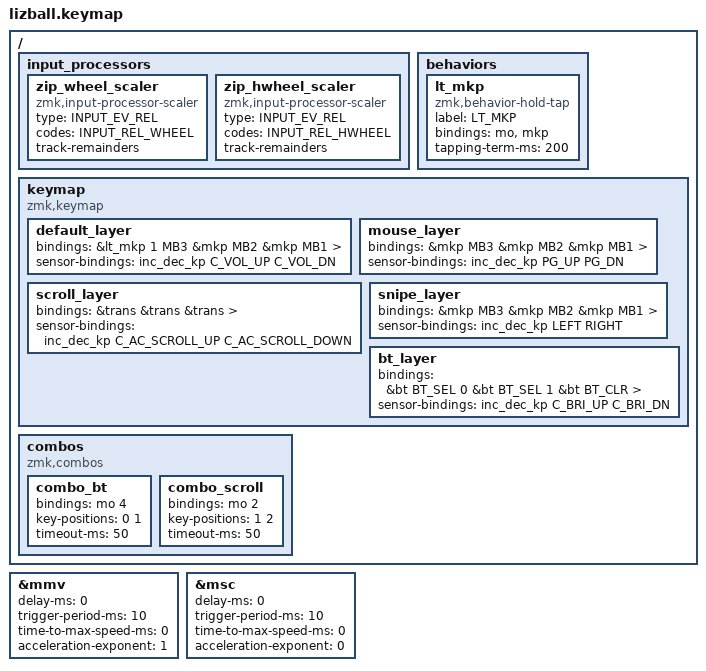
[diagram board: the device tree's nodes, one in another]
#include <dt-bindings/zmk/mouse.h>

// Default mouse movement and scroll values
#define ZMK_POINTING_DEFAULT_MOVE_VAL 800
#define ZMK_POINTING_DEFAULT_SCRL_VAL 120

#include <input/processors.dtsi>
#include <zephyr/dt-bindings/input/input-event-codes.h>
#include <behaviors.dtsi>
#include <dt-bindings/zmk/bt.h>
#include <dt-bindings/zmk/keys.h>
#include <dt-bindings/zmk/pointing.h>

// Mouse movement settings
&mmv {
    delay-ms = <0>;              // No delay
    trigger-period-ms = <10>;    // Trigger every 10ms
    time-to-max-speed-ms = <0>;  // Instant max speed
    acceleration-exponent = <1>;  // Linear acceleration
};

// Mouse scroll settings
&msc {
    delay-ms = <0>;              // No delay
    trigger-period-ms = <10>;    // Trigger every 10ms
    time-to-max-speed-ms = <0>;  // Instant max speed
    acceleration-exponent = <0>;  // No acceleration
};

// Input processors
/ {
    input_processors {
        // Vertical scroll scaler
        zip_wheel_scaler: zip_wheel_scaler {
            compatible = "zmk,input-processor-scaler";
            #input-processor-cells = <2>;
            type = <INPUT_EV_REL>;
            codes = <INPUT_REL_WHEEL>;
            track-remainders;
        };

        // Horizontal scroll scaler
        zip_hwheel_scaler: zip_hwheel_scaler {
            compatible = "zmk,input-processor-scaler";
            #input-processor-cells = <2>;
            type = <INPUT_EV_REL>;
            codes = <INPUT_REL_HWHEEL>;
            track-remainders;
        };
    };
};

// Custom behaviors
/ {
    behaviors {
        // Layer-tap and mouse click
        lt_mkp: lt_mkp {
            compatible = "zmk,behavior-hold-tap";
            label = "LT_MKP";
            bindings = <&mo>, <&mkp>;
            #binding-cells = <2>;
            tapping-term-ms = <200>;
        };
    };

    // Keymap definition
    keymap {
        compatible = "zmk,keymap";
        
        // Default layer
        default_layer {
            bindings = 
                &lt_mkp 1 MB3  &mkp MB2  &mkp MB1
            >;
            sensor-bindings = <&inc_dec_kp C_VOL_UP C_VOL_DN>;
        };
        
        // Mouse layer (activated by trackball movement)
        mouse_layer {
            bindings = 
                &mkp MB3  &mkp MB2  &mkp MB1
            >;
            sensor-bindings = <&inc_dec_kp PG_UP PG_DN>;
        };
        
        // Scroll layer
        scroll_layer {
            bindings = 
                &trans  &trans  &trans
            >;
            sensor-bindings = <&inc_dec_kp C_AC_SCROLL_UP C_AC_SCROLL_DOWN>;
        };
        
        // Precision/snipe layer
        snipe_layer {
            bindings = 
                &mkp MB3  &mkp MB2  &mkp MB1
            >;
            sensor-bindings = <&inc_dec_kp LEFT RIGHT>;
        };
        
        // Bluetooth control layer
        bt_layer {
            bindings = 
                &bt BT_SEL 0  &bt BT_SEL 1  &bt BT_CLR
            >;
            sensor-bindings = <&inc_dec_kp C_BRI_UP C_BRI_DN>;
        };
    };
};

/ {
    combos {
        compatible = "zmk,combos";

        // Press button 1+2 to enter Bluetooth layer
        combo_bt {
            bindings = <&mo 4>;
            key-positions = <0 1>;
            timeout-ms = <50>;
        };
        
        // Press button 2+3 to toggle scroll layer
        combo_scroll {
            bindings = <&mo 2>;
            key-positions = <1 2>;
            timeout-ms = <50>;
        };
    };
};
